AUTOSAR XML (schema 00046)
package /ComponentTypes
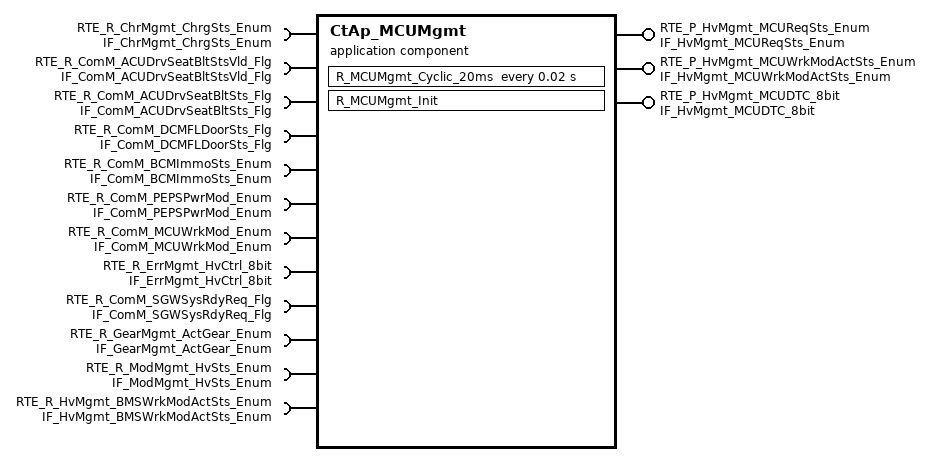
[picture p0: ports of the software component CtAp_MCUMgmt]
  application sw component type CtAp_MCUMgmt
    provide port RTE_P_HvMgmt_MCUReqSts_Enum: nonqueued-sender-com-spec{data-element=tec_HvMgmt_MCUReqSts_Enum, init-value=0}, provided-interface=IF_HvMgmt_MCUReqSts_Enum
    provide port RTE_P_HvMgmt_MCUWrkModActSts_Enum: nonqueued-sender-com-spec{data-element=tec_HvMgmt_MCUWrkModActSts_Enum, init-value=0}, provided-interface=IF_HvMgmt_MCUWrkModActSts_Enum
    provide port RTE_P_HvMgmt_MCUDTC_8bit: nonqueued-sender-com-spec{data-element=tec_HvMgmt_MCUDTC_8bit, init-value=0}, provided-interface=IF_HvMgmt_MCUDTC_8bit
    12 x require port:
      RTE_R_ChrMgmt_ChrgSts_Enum: nonqueued-receiver-com-spec{data-element=tec_ChrMgmt_ChrgSts_Enum, filter=data-filter-type=ALWAYS, init-value=0}, required-interface=IF_ChrMgmt_ChrgSts_Enum
      RTE_R_ComM_ACUDrvSeatBltStsVld_Flg: nonqueued-receiver-com-spec{data-element=tec_ComM_ACUDrvSeatBltStsVld_Flg, filter=data-filter-type=ALWAYS, init-value=0}, required-interface=IF_ComM_ACUDrvSeatBltStsVld_Flg
      RTE_R_ComM_ACUDrvSeatBltSts_Flg: nonqueued-receiver-com-spec{data-element=tec_ComM_ACUDrvSeatBltSts_Flg, filter=data-filter-type=ALWAYS, init-value=0}, required-interface=IF_ComM_ACUDrvSeatBltSts_Flg
      RTE_R_ComM_DCMFLDoorSts_Flg: nonqueued-receiver-com-spec{data-element=tec_ComM_DCMFLDoorSts_Flg, filter=data-filter-type=ALWAYS, init-value=0}, required-interface=IF_ComM_DCMFLDoorSts_Flg
      RTE_R_ComM_BCMImmoSts_Enum: nonqueued-receiver-com-spec{data-element=tec_ComM_BCMImmoSts_Enum, filter=data-filter-type=ALWAYS, init-value=0}, required-interface=IF_ComM_BCMImmoSts_Enum
      RTE_R_ComM_PEPSPwrMod_Enum: nonqueued-receiver-com-spec{data-element=tec_ComM_PEPSPwrMod_Enum, filter=data-filter-type=ALWAYS, init-value=0}, required-interface=IF_ComM_PEPSPwrMod_Enum
      RTE_R_ComM_MCUWrkMod_Enum: nonqueued-receiver-com-spec{data-element=tec_ComM_MCUWrkMod_Enum, filter=data-filter-type=ALWAYS, init-value=0}, required-interface=IF_ComM_MCUWrkMod_Enum
      RTE_R_ErrMgmt_HvCtrl_8bit: nonqueued-receiver-com-spec{data-element=tec_ErrMgmt_HvCtrl_8bit, filter=data-filter-type=ALWAYS, init-value=0}, required-interface=IF_ErrMgmt_HvCtrl_8bit
      RTE_R_ComM_SGWSysRdyReq_Flg: nonqueued-receiver-com-spec{data-element=tec_ComM_SGWSysRdyReq_Flg, filter=data-filter-type=ALWAYS, init-value=0}, required-interface=IF_ComM_SGWSysRdyReq_Flg
      RTE_R_GearMgmt_ActGear_Enum: nonqueued-receiver-com-spec{data-element=tec_GearMgmt_ActGear_Enum, filter=data-filter-type=ALWAYS, init-value=0}, required-interface=IF_GearMgmt_ActGear_Enum
      RTE_R_ModMgmt_HvSts_Enum: nonqueued-receiver-com-spec{data-element=tec_ModMgmt_HvSts_Enum, filter=data-filter-type=ALWAYS, init-value=0}, required-interface=IF_ModMgmt_HvSts_Enum
      RTE_R_HvMgmt_BMSWrkModActSts_Enum: nonqueued-receiver-com-spec{data-element=tec_HvMgmt_BMSWrkModActSts_Enum, filter=data-filter-type=ALWAYS, init-value=0}, required-interface=IF_HvMgmt_BMSWrkModActSts_Enum
    behavior CtAp_MCUMgmt_InternalBehavior
      init event CtAp_MCUMgmt_InitEvent: start-on-event=R_MCUMgmt_Init
      timing event TMT_R_MCUMgmt_Cyclic_20ms: start-on-event=R_MCUMgmt_Cyclic_20ms, period=0.02
      runnable R_MCUMgmt_Init
      runnable R_MCUMgmt_Cyclic_20ms
        data-receive-point-by-arguments:
          12 x access:
            REC_RTE_R_ChrMgmt_ChrgSts_Enum_tec_ChrMgmt_ChrgSts_Enum: accessed-variable=RTE_R_ChrMgmt_ChrgSts_Enum.tec_ChrMgmt_ChrgSts_Enum
            REC_RTE_R_ComM_ACUDrvSeatBltStsVld_Flg_tec_ComM_ACUDrvSeatBltStsVld_Flg: accessed-variable=RTE_R_ComM_ACUDrvSeatBltStsVld_Flg.tec_ComM_ACUDrvSeatBltStsVld_Flg
            REC_RTE_R_ComM_ACUDrvSeatBltSts_Flg_tec_ComM_ACUDrvSeatBltSts_Flg: accessed-variable=RTE_R_ComM_ACUDrvSeatBltSts_Flg.tec_ComM_ACUDrvSeatBltSts_Flg
            REC_RTE_R_ComM_BCMImmoSts_Enum_tec_ComM_BCMImmoSts_Enum: accessed-variable=RTE_R_ComM_BCMImmoSts_Enum.tec_ComM_BCMImmoSts_Enum
            REC_RTE_R_ComM_DCMFLDoorSts_Flg_tec_ComM_DCMFLDoorSts_Flg: accessed-variable=RTE_R_ComM_DCMFLDoorSts_Flg.tec_ComM_DCMFLDoorSts_Flg
            REC_RTE_R_ComM_MCUWrkMod_Enum_tec_ComM_MCUWrkMod_Enum: accessed-variable=RTE_R_ComM_MCUWrkMod_Enum.tec_ComM_MCUWrkMod_Enum
            REC_RTE_R_ComM_PEPSPwrMod_Enum_tec_ComM_PEPSPwrMod_Enum: accessed-variable=RTE_R_ComM_PEPSPwrMod_Enum.tec_ComM_PEPSPwrMod_Enum
            REC_RTE_R_ComM_SGWSysRdyReq_Flg_tec_ComM_SGWSysRdyReq_Flg: accessed-variable=RTE_R_ComM_SGWSysRdyReq_Flg.tec_ComM_SGWSysRdyReq_Flg
            REC_RTE_R_ErrMgmt_HvCtrl_8bit_tec_ErrMgmt_HvCtrl_8bit: accessed-variable=RTE_R_ErrMgmt_HvCtrl_8bit.tec_ErrMgmt_HvCtrl_8bit
            REC_RTE_R_GearMgmt_ActGear_Enum_tec_GearMgmt_ActGear_Enum: accessed-variable=RTE_R_GearMgmt_ActGear_Enum.tec_GearMgmt_ActGear_Enum
            REC_RTE_R_HvMgmt_BMSWrkModActSts_Enum_tec_HvMgmt_BMSWrkModActSts_Enum: accessed-variable=RTE_R_HvMgmt_BMSWrkModActSts_Enum.tec_HvMgmt_BMSWrkModActSts_Enum
            REC_RTE_R_ModMgmt_HvSts_Enum_tec_ModMgmt_HvSts_Enum: accessed-variable=RTE_R_ModMgmt_HvSts_Enum.tec_ModMgmt_HvSts_Enum
        data-send-points:
          access SEND_RTE_P_HvMgmt_MCUDTC_8bit_tec_HvMgmt_MCUDTC_8bit: accessed-variable=RTE_P_HvMgmt_MCUDTC_8bit.tec_HvMgmt_MCUDTC_8bit
          access SEND_RTE_P_HvMgmt_MCUReqSts_Enum_tec_HvMgmt_MCUReqSts_Enum: accessed-variable=RTE_P_HvMgmt_MCUReqSts_Enum.tec_HvMgmt_MCUReqSts_Enum
          access SEND_RTE_P_HvMgmt_MCUWrkModActSts_Enum_tec_HvMgmt_MCUWrkModActSts_Enum: accessed-variable=RTE_P_HvMgmt_MCUWrkModActSts_Enum.tec_HvMgmt_MCUWrkModActSts_Enum
  swc implementation CtAp_MCUMgmt_Implementation: behavior=CtAp_MCUMgmt_InternalBehavior
    code-descriptors:
      code Default: artifact-descriptors=autosar-engineering-object=category=SWOBJ
